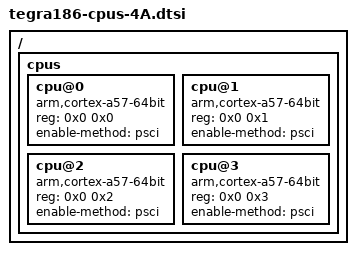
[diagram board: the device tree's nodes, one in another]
/*
 * arch/arm64/boot/dts/tegra186-cpus-4A.dtsi
 *
 * Copyright (c) 2014, NVIDIA CORPORATION.  All rights reserved.
 *
 * This program is free software; you can redistribute it and/or modify
 * it under the terms of the GNU General Public License as published by
 * the Free Software Foundation; version 2 of the License.
 *
 * This program is distributed in the hope that it will be useful, but WITHOUT
 * ANY WARRANTY; without even the implied warranty of MERCHANTABILITY or
 * FITNESS FOR A PARTICULAR PURPOSE.  See the GNU General Public License for
 * more details.
 *
 * You should have received a copy of the GNU General Public License along
 * with this program; if not, write to the Free Software Foundation, Inc.,
 * 51 Franklin Street, Fifth Floor, Boston, MA  02110-1301, USA.
 *
 */

/ {
	cpus {
		#address-cells = <2>;
		#size-cells = <0>;

		cpu@0 {
			device_type = "cpu";
			compatible = "arm,cortex-a57-64bit", "arm,armv8";
			reg = <0x0 0x0>;
			enable-method = "psci";
		};

		cpu@1 {
			device_type = "cpu";
			compatible = "arm,cortex-a57-64bit", "arm,armv8";
			reg = <0x0 0x1>;
			enable-method = "psci";
		};

		cpu@2 {
			device_type = "cpu";
			compatible = "arm,cortex-a57-64bit", "arm,armv8";
			reg = <0x0 0x2>;
			enable-method = "psci";
		};

		cpu@3 {
			device_type = "cpu";
			compatible = "arm,cortex-a57-64bit", "arm,armv8";
			reg = <0x0 0x3>;
			enable-method = "psci";
		};
	};
};
